# SPC1068 register map
File version: 20180100_70611510
CPU: CM3 r2p1, little endian, MPU, no FPU, 4 interrupt priority bits
Registers are 32-bit, read-write, reset 0x0 unless marked. A register's access mark holds for its fields unless they carry their own. Offsets are from the block's base; [hi:lo] are bit positions; {n}, {i} and the like mark numbered series; <NAME> marks a mode.

## UART — NOEN
Base 0x40004000
0x00 UARTDLL reset 0x2 — UART Divisor Latch Low Byte Register
  [7:0] VAL — Low-byte compare value to generate baud rate
0x00 UARTRBR ro (alternate view of UARTDLL) — UART Receive Buffer Register
  [31:0] VAL — In non-FIFO mode, this register holds the characters received by the UART Receive Shift Register. If this register is configured to use fewer than eight bits, the bits are right-justified and the most significant bits (MSB) are zeroed. Reading the register empties the register and clears the <Data Ready> field in the Line Status Register. UARTRBR latches the value of the data byte at the front of the FIFO in FIFO mode.
0x00 UARTTHR wo (alternate view of UARTDLL) — UART Transmit Holding Register
  [31:0] VAL — This register holds the data byte to be transmitted next in non-FIFO mode. When the Transmit Shift Register (TSR) is emptied, the contents of this register are loaded into the Transmit Shift Register and the <Transmit Data Request> field in the Line Status Register is set. A write to Transmit Holding Register puts data into the top of the FIFO in FIFO mode. The data at the front of the FIFO is loaded into the TSR when the TSR is empty.
0x04 UARTDLH — UART Divisor Latch High Byte Register
  [7:0] VAL — High-byte compare value to generate baud rate
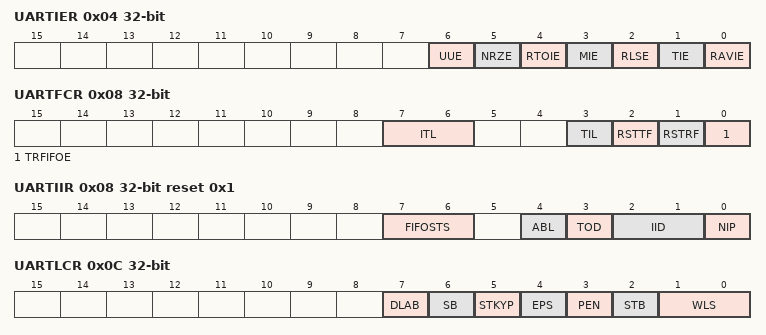
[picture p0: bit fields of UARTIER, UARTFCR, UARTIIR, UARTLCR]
0x04 UARTIER (alternate view of UARTDLH) — UART Interrupt Enable Register
  [6] UUE — UART Unit Enable
    0=UART_DISABLE (The unit is disabled); 1=UART_ENABLE (The unit is enabled)
  [5] NRZE — NRZ coding Enable. NRZ encoding/decoding is used only in UART mode, not in Infrared mode. If the serial infrared receiver or transmitter is enabled, NRZ coding is disabled.
    0=NRZ_DISABLE (NRZ coding disabled); 1=NRZ_ENABLE (NRZ coding enabled)
  [4] RTOIE — Receiver Time-out Interrupt Enable. Receiver Time-out Interrupt Enable (Source UARTIIR[TOD])
    0=RX_TIMEOUT_INT_DISABLE (Receiver data time-out interrupt disabled); 1=RX_TIMEOUT_INT_ENABLE (Receiver data time-out interrupt enabled)
  [3] MIE — Modem Interrupt Enable. Modem Interrupt Enable (Source UARTIIR[IID])
    0=MODEM_INT_DISABLE (Modem status interrupt disabled); 1=MODEM_INT_ENABLE (Modem status interrupt enabled)
  [2] RLSE — Receiver Line Status Interrupt Enable. Receiver Line Status Interrupt Enable (Source UARTIIR[IID])
    0=RX_LINE_INT_DISABLE (Receiver line status interrupt disabled); 1=RX_LINE_INT_ENABLE (Receiver line status interrupt enabled)
  [1] TIE — Transmit Data Request Interrupt Enable. Transmit Data Request Interrupt Enable (Source UARTIIR[IID])
    0=TX_FIFO_INT_DISABLE (Transmit FIFO data request interrupt disabled); 1=TX_FIFO_INT_ENABLE (Transmit FIFO data request interrupt enabled)
  [0] RAVIE — Receiver Data Available Interrupt Enable. Receiver Data Available Interrupt Enable (Source UARTIIR[IID])
    0=RX_DATA_INT_DISABLE (Receiver data available (trigger threshold reached) interrupt disable); 1=RX_DATA_INT_ENABLE (Receiver data available (trigger threshold reached) interrupt enabled)
0x08 UARTFCR wo — UART FIFO Control Register
  [7:6] ITL — Interrupt Trigger Level (threshold). When the number of bytes in the Receive FIFO equals the interrupt trigger threshold programmed into this field and the received-data-available interrupt is enabled via the UARTIER, an interrupt is generated and appropriate bits are set in the UARTIIR.
    0=RX_FIFO_THRESHOLD_1 (1 byte or more in FIFO causes interrupt); 1=RX_FIFO_THRESHOLD_8 (8 bytes or more in FIFO causes interrupt); 2=RX_FIFO_THRESHOLD_16 (16 bytes or more in FIFO causes interrupt); 3=RX_FIFO_THRESHOLD_32 (32 bytes or more in FIFO causes interrupt)
  [3] TIL — Transmitter Interrupt Level
    0=TXFIFO_HALF_EMPTY (Interrupt request when FIFO is half empty); 1=TXFIFO_EMPTY (Interrupt request when FIFO is empty)
  [2] RSTTF — Reset Transmit FIFO. When this one is set, all the bytes in the Transmit FIFO are cleared. The TDRQ bit in the LSR is set and the UARTIIR shows a transmitter requests data interrupt, if the TIE bit in the UARTIER register is set. The transmit Shift register is not cleared, and it completes the current transmission.
    0=NO_EFFECT (Writing 0 has no effect); 1=CLEAR_TX_FIFO (The transmit FIFO is cleared)
  [1] RSTRF — Reset Receive FIFO. When RESETRF is set, all the bytes in the Receive FIFO are cleared. The DR bit in the UARTLSR is cleared to 0. All the error bits in the FIFO and the FIFOE bit in the UARTLSR are cleared. Any error bits, OE, PE, FE or BI, that has been set in UARTLSR are still set. The Receive Shift Register is not cleared. If the UARTIIR has been set to "received data available", it is cleared.
    0=NO_EFFECT (Writing 0 has no effect); 1=CLEAR_RX_FIFO (The receive FIFO is cleared)
  [0] TRFIFOE — Transmit and Receive FIFO Enable. TRFIFOE enable or disables the Transmit and Receive FIFOs. When TRFIFOE is set, both FIFOs are enabled (FIFO mode). When TRFIFOE is clear, the FIFOs are both disabled (non-FIFO mode). Writing 0b0 to this bit clears all bytes in both FIFOs. When changing from FIFO mode to non-FIFO mode and vice versa, data is cleared automatically from the FIFOs. This bit must be set when other bits in this register are written or the othe r bits are not programmed.
    0=FIFO_DISABLE (FIFOs are disabled); 1=FIFO_ENABLE (FIFOs are enabled)
0x08 UARTIIR ro reset 0x1 (alternate view of UARTFCR) — UART Interrupt Identification Register
  [7:6] FIFOSTS — FIFO Mode Enable Status
    0=NOT_FIFO_MODE (Non-FIFO mode is selected); 3=FIFO_MODE (FIFO mode is selected (<Transmit and Receive FIFO Enable> field in the FIFO Control Register = 1))
  [4] ABL — Auto-baud Lock
    0=AUTO_BAUD_NOT_LOCK (Auto-baud circuitry has not programmed Divisor Latch registers (DLR)); 1=AUTO_BAUD_LOCK (Divisor Latch registers (DLR) programmed by auto-baud circuitry)
  [3] TOD — Time Out Detected
    0=TIMEOUT_NOT_OCCUR (No time out interrupt is pending); 1=TIMEOUT_OCCUR (Time out interrupt is pending (FIFO mode only))
  [2:1] IID — Interrupt Source Encoded
    0=MODEM_INT (Modem Status (CTS, DSR, RI, DCD modem signals changed state), Do not support in SPC1068); 1=TX_FIFO_REQUEST_DATA_INT (Transmit FIFO requests data); 2=RX_DATA_READY_INT (Received data available); 3=RX_ERROR_INT (Receive error (Overrun, parity, framing, break, FIFO error))
  [0] NIP — No Interrupt Pending
    0=INT_OCCUR (Interrupt is pending (active low)); 1=INT_NOT_OCCUR (No interrupt is pending)
0x0C UARTLCR — UART Line Control Register
  [7] DLAB — Divisor Latch Access Bit. Must be set to access the Divisor Latch registers of the baud-rate generator during a Read or Write operation. Must be clear to access the Receive buffer, the Transmit Holding Register, or the UARTIER.
    0=DIVISOR_LOCK (Access Transmit Holding Register, Receive Buffer Register, and Interrupt Enable Register); 1=DIVISOR_ACCESS (Access Divisor Latch registers (UARTDLL and UARTDLH))
  [6] SB — Set Break. Causes a break condition to be transmitted to the receiving UART. Acts only on the TXD pin and has no effect on the Transmit logic. In FIFO mode, wait until the transmitter is idle (UARTLSR[TXEMPTY]=1) to set and clear SB.
    0=NO_EFFECT (No effect on TXD output); 1=FORCE_TX_0 (Forces TXD output to 0 (space))
  [5] STKYP — Sticky Parity. Forces the bit value at the parity bit location to be the opposite of the EPS bit rather than the parity value. This stops parity generation. If PEN=0, STKYP is ignored.
    0=NO_EFFECT (No effect on parity bit); 1=PARITY_EQU_INVERT_EPS (Forces parity bit to be opposite of EPS bit value)
  [4] EPS — Even Parity Select. If PEN = 0, EPS is ignored.
    0=ODD_PARITY (Sends or checks for odd parity); 1=EVEN_PARITY (Sends or checks for even parity)
  [3] PEN — Parity Enable. Enables a parity bit to be generated on transmission or checked on reception.
    0=NO_PARITY; 1=PARITY_ENABLE
  [2] STB — Stop bits. Specifies the number of stop bits transmitted and received in each character. When receiving, the receiver checks only the first stop bit.
    0=1_STOP_BIT; 1=2_STOP_BIT (1.5 stop bits for 5-bit character. 2 stop bits for 6/7/8 bit character)
  [1:0] WLS — Word Length Select. Specifies the number of data bits in each transmitted or received character.
    {v}={v+5}_DATA_BIT ({v+5}-bit character) (v=0..3)
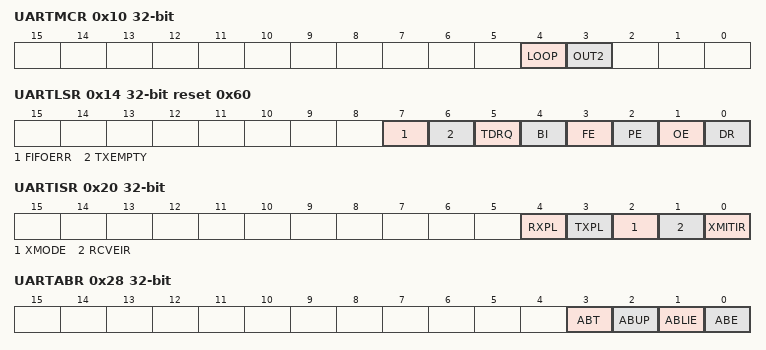
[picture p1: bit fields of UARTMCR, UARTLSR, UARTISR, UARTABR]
0x10 UARTMCR — UART Modem Control Register
  [4] LOOP — Loopback Mode. This bit provides a local loopback feature for diagnostic testing of the UART. When LOOP is set, the following occurs: The transmitter serial output is set to a logic 1 state. The receiver serial input is disconnected from the pin. The output of the Transmit Shift Register is looped back into the Receive Shift Register input. Loopback mode must be configured before the UART is enabled. In Loopback mode, data that is transmitted is received immediately. This feature allows the CPU to verify the Transmit and Receive data paths of the UART. A break signal can also be transferred from the transmitter section to the receiver section in Loopback mode.
    0=NORMAL_MODE (Normal UART operation); 1=LOOPBACK_MODE (Loopback-mode UART operation)
  [3] OUT2 — OUT2 Signal Control. OUT2 connects the UART interrupt output to the Interrupt Controller unit when LOOP is clear. When LOOP is set, interrupts always go to the CPU.
    0=INT_DISABLE (Disable UART interrupt); 1=INT_ENABLE (Enable UART interrupt)
0x14 UARTLSR ro reset 0x60 — UART Line Status Register
  [7] FIFOERR — FIFO Error Status. This bit is clear in non-FIFO mode. In FIFO mode, FIFOERR is set when there is at least one parity error, framing error, or break indication for any of the characters in the FIFO. The CPU read of the UARTLSR does not reset this bit. FIFOERR is reset when all errorneous characters have been read from the FIFO.
    0=FIFO_ERROR_NOT_OCCUR (No FIFO or no errors in receive FIFO); 1=FIFO_ERROR_OCCUR (At least one character in receive FIFO has errors)
  [6] TXEMPTY — Transmitter Empty. Set when the Transmit Holding Register and the Transmit Shift Register are both empty. It is cleared when either the Transmit Holding Register or the Transmit Shift Register contains a data character. In FIFO mode, TXEMPTY is set when the Transmit FIFO and the Transmit Shift Register are both empty.
    0=TXFIFO_NOT_EMPTY (There is data in the transmit shift register, the Transmit Holding Register, or the FIFO.); 1=TXFIFO_EMPTY (All the data in the transmitter has been shifted out)
  [5] TDRQ — Transmit Data Request. Indicates that the UART is ready to accept a new character for transmission. In addition, this bit causes the UART to issue an interrupt to the CPU when the transmit-data request interrupt enable is set. The TDRQ bit is set when a character is transferred from the Transmit Holding Register into the Transmit Shift Register. The bit is cleared with the loading of the Transmit Holding Register. In FIFO mode, TDRQ is set when half of the characters in the FIFO have been loaded into the Shift Register or the RESETTF bit in UARTFCR has been set. It is cleared when the FIFO has more than half data. If more than 64 characters are loaded into the FIFO, the excess characters are lost.
    0=TXFIFO_MORE_THAN_HALF (There is data in the holding register or FIFO waiting to be shifted out); 1=TXFIFO_LESS_THAN_HALF (The transmit FIFO has half or less than half data)
  [4] BI — Break Interrupt. BI is set when the received data input is held low for longer than a full-word transmission time (the total time of start bit + data bits + parity bit + stop bit). BI is cleared when the CPU reads the UARTLSR. In FIFO mode, only one character equal to 0x00, is loaded into the FIFO regardless of the length of the break condition. BI shows the break condition for the character at the front of the FIFO, not the most recently received character.
    0=BREAK_SIGNAL_NOT_OCCUR (No break signal has been received); 1=BREAK_SIGNAL_OCCUR (Break signal received)
  [3] FE — Framing Error. FE indicates that the received character did not have a valid stop bit. FE is set when the bit following the last data bit or parity bit is detected to be 0. FE is cleared when the CPU reads the LSR. The UART resynchronizes after a framing error. To do this, it assumes that the framing error was due to the next start bit, so it samples this start bit twice and then reads in the data. In FIFO mode, FE shows a framing error for the character at the front of the FIFO, not for the most recently received character.
    0=FRAME_ERROR_NOT_OCCUR (No Framing error); 1=FRAME_ERROR_OCCUR (Invalid stop bit has been detected)
  [2] PE — Parity Error. Indicates that the received data character does not have the correct even or odd parity, as selected by the even parity select bit. PE is set upon detection of a parity error and is cleared when the CPU reads the UARTLSR. In FIFO mode, PE shows a parity error for the character at the front of the FIFO, not the most recently received character.
    0=PARITY_ERROR_NOT_OCCUR (No Parity Error); 1=PARITY_ERROR_OCCUR (Parity error has occurred)
  [1] OE — Overrun Error. In non-FIFO mode, indicates that data in Receive Buffer register was not read by the CPU before the next character was received. The new character is lost. In FIFO mode, OE indicates that all 64 bytes of the FIFO are full and the most recently received byte has been discarded. OE is set upon detection of an overrun condition and cleared when the CPU reads the UARTLSR.
    0=RX_OVERRUN_NOT_OCCUR (No data has been overrun); 1=RX_OVERRUN_OCCUR (Receive data has been overrun)
  [0] DR — Data Ready. Set when a complete incoming character has been received and transferred into the Receive Buffer Register or the FIFO. In non-FIFO mode, DR is cleared when the Receive buffer is read. In FIFO mode, DR is cleared if the FIFO is empty (last character has been read from UARTRBR) or the FIFO is reset with UARTFCR[RESETRF].
    0=NO_DATA_RECEVIED (No data has been received); 1=DATA_RECEVIED (Data is available in UARTRBR or the FIFO)
0x20 UARTISR — UART Infrared Selection Register
  [4] RXPL — Receive Data Polarity
    0=REV_POSITIVE_ZERO (SIR decoder takes positive pulses as zeros); 1=REV_NEGATIVE_ZERO (SIR decoder takes negative pulses as zeros)
  [3] TXPL — Transmit Data Polarity
    0=SEND_POSITIVE_ZERO (SIR encoder generates a positive pulse for a data bit of zero); 1=SEND_NEGATIVE_ZERO (SIR encoder generates a negative pulse for a data bit of zero)
  [2] XMODE — Transmit Pulse Width Select. When XMODE is clear, the UART 16x clock is used to clock the lrDA Transmit and Receive logic. When XMDOE is set, Receive decoder operaton does not change, and the Transmit encoder generates 1.6 ms pulses (that are 3/16 of a bit time at 115.2 kbps) instead of pulses 3/16 of a bit time wide. Spintrol recommends setting XMDOE.
    0=WIDTH_3OVER16 (Transmit pulse width is 3/16 of a bit time wide); 1=WIDTH_1DOT6_MS (Transmit pulse width is 1.6ms)
  [1] RCVEIR — Receiver SIR Enable. When RCVEIR is set, the signal from the RXD pin is processed by lrDA decoder before it is fed to the UART. IF RCVEIR is clear, than all clocking to the lrDA decoder is blocked and the RXD pin is fed directly to the UART.
    0=UART (Receiver is in UART mode); 1=INFRARED (Receiver is in infrared mode)
  [0] XMITIR — Transmitter SIR Enable. When XMITIR is set, the normal TXD output from the UART is processed by the lrDA encoder before it is fed to the device pin. If XMITIR is clear, all clocking to the lrDA encoder is blocked and the UART's TXD signal is connected directly to the device pin.
    0=TXD_BY_IRDA (TXD output from the UART is processed by the lrDA encoder); 1=TXD_DIRECT (TXD signal is connected directly)
0x24 UARTFOR ro — UART Receive FIFO Occupancy Register
  [5:0] BYTECNT — Number of bytes (0-63) remaining in the Receive FIFO
0x28 UARTABR — UART Auto-Baud Control Register
  [3] ABT — Method to calculate baud rates
    0=FORMULA (Formula used to calculate baud rates, allowing all possible baud rates to be chosen by UART as shown in this chapter); 1=TABLE (Table used to calculate baud rates, which limits UART to choosing common baud rates)
  [2] ABUP — Method to program Divisor Latch registers
    0=SOFTWARE_PROG_DIVISOR (Software Programs Divisor Latch registers); 1=UART_PROG_DIVISOR (UART Programs Divisor Latch registers)
  [1] ABLIE — Auto-baud-lock interrupt enable
    0=DISABLE (Auto-baud-lock interrupt disabled (Source UARTIIR[ABL])); 1=ENABLE (Auto-baud-lock interrupt enabled (Source UARTIIR[ABL]))
  [0] ABE — Auto-baud detection enable
    0=DISABLE (Auto-baud disabled); 1=ENABLE (Auto-baud enabled)
0x2C UARTACR ro — UART Auto-Baud Count Register
  [15:0] CNTVAL — Number of UART clock cycles within a start-bit pulse
